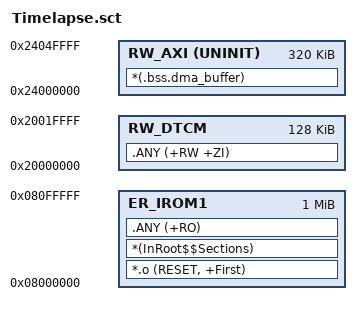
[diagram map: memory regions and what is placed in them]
; STM32H723VG: код во Flash, данные/стек в DTCM, кадр DCMI в AXI SRAM.
LR_IROM1 0x08000000 0x00100000
{
  ER_IROM1 0x08000000 0x00100000
  {
    *.o (RESET, +First)
    *(InRoot$$Sections)
    .ANY (+RO)
  }
  RW_AXI 0x24000000 UNINIT 0x00050000
  {
    *(.bss.dma_buffer)
  }
  RW_DTCM 0x20000000 0x00020000
  {
    .ANY (+RW +ZI)
  }
}
